# SAMA7G54D2G device description
Architecture: CORTEX-A7; Family: SAMA; Series: SAMA7G
Registers are 32-bit, read-write, reset 0x0 unless marked. A register's access mark holds for its fields unless they carry their own. Offsets are from the block's base; [hi:lo] are bit positions; {n}, {i} and the like mark numbered series.

## PDMC — Pulse Density Microphone Controller
Instances: PDMC0 0xE1608000, PDMC1 0xE160C000
0x00 PDMC_CR wo reset not defined — Control Register
  [0] SWRST — Software Reset
    0=No effect; 1=Resets the PDMC interface
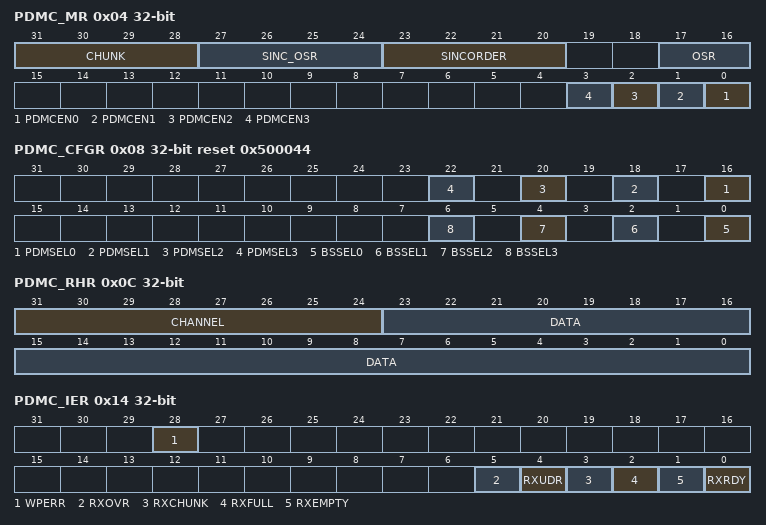
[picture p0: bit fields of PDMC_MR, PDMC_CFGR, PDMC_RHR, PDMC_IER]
0x04 PDMC_MR — Mode Register
  [31:28] CHUNK — Chunk Size
  [27:24] SINC_OSR — SINC Filter Oversampling Ratio
    0=DISABLE (Audio filtering mode. The SINC filter OSR is implicitly defined by the PDMC_MR.OSR field.); 1=OSR8 (The SINC filter OSR is 8.); 2=OSR16 (The SINC filter OSR is 16.); 3=OSR32 (The SINC filter OSR is 32.); 4=OSR64 (The SINC filter OSR is 64.); 5=OSR128 (The SINC filter OSR is 128.); 6=OSR256 (The SINC filter OSR is 256.)
  [23:20] SINCORDER — SINC Filter Order
    1=ORDER1 (SINC filter order is 1.); 2=ORDER2 (SINC filter order is 2.); 3=ORDER3 (SINC filter order is 3. Recommended if SINC_OSR=0); 4=ORDER4 (SINC filter order is 4.); 5=ORDER5 (SINC filter order is 5.)
  [17:16] OSR — Audio Oversampling Ratio
    1=OSR is 64; 2=OSR is 128; 3=OSR is 256
  [n] PDMCEN{n} (n=0..3) — PDMC Channel {n} Enable
    0=DISABLE (PDMC is disabled.); 1=ENABLE (PDMC is enabled.)
0x08 PDMC_CFGR reset 0x500044 — Configuration Register
  [2n+16] PDMSEL{n} (n=0..3) — PDM Microphone Source Selection
    0=PDMSELx corresponds to PMDC_DS0; 1=PDMSELx corresponds to PMDC_DS1
  [2n] BSSEL{n} (n=0..3) — Bitstream Source Selection
    0=The selected PDMC_DSx source is sampled on positive edge of PDMC_CLK; 1=The selected PDMC_DSx source is sampled on negative edge of PDMC_CLK
0x0C PDMC_RHR ro — Receive Holding Register
  [31:24] CHANNEL — Channel Index of Data
  [23:0] DATA — Converted Data
0x14 PDMC_IER wo reset not defined (atomic set of PDMC_IMR) — Interrupt Enable Register
  [28] WPERR — Write Protection Error Enable
  [5] RXOVR — Receive Over Flow Interrupt Enable
  [4] RXUDR — Receive Under Flow Interrupt Enable
  [3] RXCHUNK — Receive FIFO Chunk Interrupt Enable
  [2] RXFULL — Receive FIFO Full Interrupt Enable
  [1] RXEMPTY — Receive FIFO Empty Interrupt Enable
  [0] RXRDY — Receive Ready Interrupt Enable
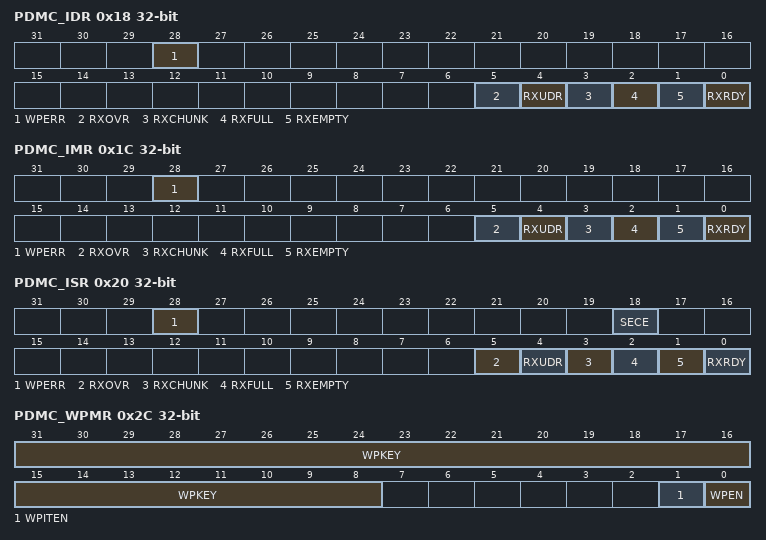
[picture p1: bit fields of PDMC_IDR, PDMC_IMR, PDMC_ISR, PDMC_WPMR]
0x18 PDMC_IDR wo reset not defined (atomic clear of PDMC_IMR) — Interrupt Disable Register
  [28] WPERR — Write Protection Error Disable
  [5] RXOVR — Receive Over Flow Interrupt Disable
  [4] RXUDR — Receive Under Flow Interrupt Disable
  [3] RXCHUNK — Receive FIFO Chunk Interrupt Disable
  [2] RXFULL — Receive FIFO Full Interrupt Disable
  [1] RXEMPTY — Receive FIFO Empty Interrupt Disable
  [0] RXRDY — Receive Ready Interrupt Disable
0x1C PDMC_IMR ro — Interrupt Mask Register
  [28] WPERR — Write Protection Error Mask
  [5] RXOVR — Receive Over Flow Interrupt Mask
  [4] RXUDR — Receive Under Flow Interrupt Mask
  [3] RXCHUNK — Receive FIFO Chunk Interrupt Mask
  [2] RXFULL — Receive FIFO Full Interrupt Mask
  [1] RXEMPTY — Receive FIFO Empty Interrupt Mask
  [0] RXRDY — Receive Ready Interrupt Mask
0x20 PDMC_ISR ro — Interrupt Status Register
  [28] WPERR — Write Protection Error Status (cleared on read)
    0=No write protection error event occurred since the last read of PDMC_ISR; 1=At least one write protection error event occurred since the last read of PDMC_ISR
  [18] SECE — Security and/or Safety Event (cleared on read)
    0=No security or safety event has occurred since the last read of PDMC_ISR; 1=One or more safety or security event occurred since the last read of PDMC_ISR. For details on the event, see PDMC Write Protection Status Register.
  [5] RXOVR — Receive Over Flow Interrupt Status (cleared on read)
    0=No overflow event occurred since the last read of PDMC_ISR; 1=At least one overflow event occurred since the last read of PDMC_ISR
  [4] RXUDR — Receive Under Flow Interrupt Status (cleared on read)
    0=No underflow event occurred since the last read of PDMC_ISR; 1=At least one underflow event occurred since the last read of PDMC_ISR
  [3] RXCHUNK — Receive FIFO Chunk Interrupt Status
    0=There is less than PDMC_MR.CHUNK data in the RX FIFO; 1=At least PDMC_MR.CHUNK data can be read in the RX FIFO
  [2] RXFULL — Receive FIFO Full Interrupt Status
    0=The RX FIFO is not full and can still receive data; 1=The RX FIFO is full and cannot receive more data
  [1] RXEMPTY — Receive FIFO Empty Interrupt Status
    0=At least one data is in the RX FIFO; 1=The RX FIFO is empty
  [0] RXRDY — Receive Ready Interrupt Status
    0=There is no data in the RX FIFO; 1=At least one data is in the RX FIFO and can be read through the PDMC_RHR register
0x2C PDMC_WPMR — Write Protection Mode Register
  [31:8] WPKEY — Write Protection Key
    0x50444D=PASSWD (Writing any other value in this field aborts the write operation of the WPEN and WPITEN bits. Always read at 0.)
  [1] WPITEN — Write Protection Interrupt Enable
    0=Disables the write protection on interrupt registers if WPKEY corresponds to 0x50444D ("PDM" in ASCII); 1=Enables the write protection on interrupt registers if WPKEY corresponds to 0x50444D ("PDM" in ASCII)
  [0] WPEN — Write Protection Enable
    0=Disables write protection if WPKEY corresponds to 0x50444D ("PDM" in ASCII); 1=Enables write protection if WPKEY corresponds to 0x50444D ("PDM" in ASCII)
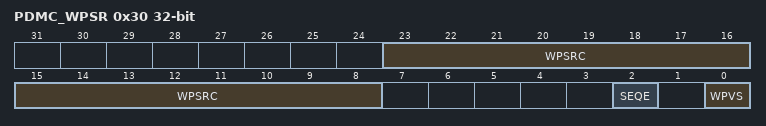
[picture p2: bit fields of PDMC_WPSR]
0x30 PDMC_WPSR ro — Write Protection Status Register
  [23:8] WPSRC — Write Protection Source
  [2] SEQE — Internal Sequencer Error
    0=No peripheral internal sequencer error has occurred since the last read of PDMC_WPSR; 1=A peripheral internal sequencer error has occurred since the last read of PDMC_WPSR
  [0] WPVS — Write Protection Violation Status
    0=No write protection violation has occurred since the last read of PDMC_WPSR; 1=A write protection violation has occurred since the last read of PDMC_WPSR. If this violation is an unauthorized attempt to write a protected register, the associated violation is reported into field WPSRC.
